# ATtiny416 device description
Architecture: AVR8X; Family: AVR TINY
Registers are 8-bit, read-write, reset 0x0 unless marked. A register's access mark holds for its fields unless they carry their own. Offsets are from the block's base; [hi:lo] are bit positions.

## CPU
Instances: CPU 0x0030
0x04 CCP — Configuration Change Protection
  [7:0] CCP — CCP signature
    157=SPM (SPM Instruction Protection); 216=IOREG (IO Register Protection)
0x0D SPL reset not defined — Stack Pointer Low
0x0E SPH reset not defined — Stack Pointer High
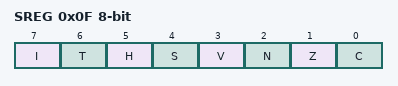
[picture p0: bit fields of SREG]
0x0F SREG — Status Register
  [7] I — Global Interrupt Enable Flag
  [6] T — Transfer Bit
  [5] H — Half Carry Flag
  [4] S — N Exclusive Or V Flag
  [3] V — Two's Complement Overflow Flag
  [2] N — Negative Flag
  [1] Z — Zero Flag
  [0] C — Carry Flag

## CPUINT — Interrupt Controller
Instances: CPUINT 0x0110
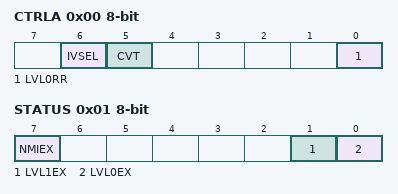
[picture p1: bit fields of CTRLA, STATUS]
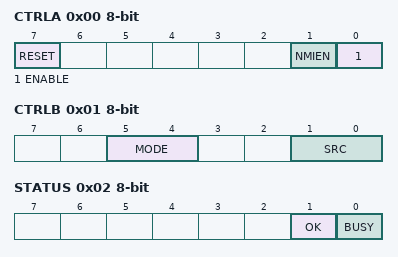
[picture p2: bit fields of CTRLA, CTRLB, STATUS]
0x00 CTRLA — Control A
  [6] IVSEL — Interrupt Vector Select
  [5] CVT — Compact Vector Table
  [0] LVL0RR — Round-robin Scheduling Enable
0x01 STATUS
  [7] NMIEX ro — Non-maskable Interrupt Executing
  [1] LVL1EX ro — Level 1 Interrupt Executing
  [0] LVL0EX ro — Level 0 Interrupt Executing
0x02 LVL0PRI — Interrupt Level 0 Priority
  [7:0] LVL0PRI — Interrupt Level Priority
0x03 LVL1VEC — Interrupt Level 1 Priority Vector
  [7:0] LVL1VEC — Interrupt Vector with High Priority

## CRCSCAN
Instances: CRCSCAN 0x0120
0x00 CTRLA — Control A
  [7] RESET — Reset CRC scan
  [1] NMIEN — Enable NMI Trigger
  [0] ENABLE — Enable CRC scan
0x01 CTRLB — Control B
  [5:4] MODE — CRC Flash Access Mode
    0=PRIORITY (Priority to flash); 2=BACKGROUND (Lowest priority to flash); 3=CONTINUOUS (Continuous checks in background)
  [1:0] SRC — CRC Source
    0=FLASH (CRC on entire flash); 1=APPLICATION (CRC on boot and appl section of flash); 2=BOOT (CRC on boot section of flash)
0x02 STATUS ro
  [1] OK — CRC Ok
  [0] BUSY — CRC Busy

## DAC — Digital to Analog Converter
Instances: DAC0 0x0680
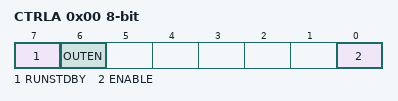
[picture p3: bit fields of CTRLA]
0x00 CTRLA — Control Register A
  [7] RUNSTDBY — Run in Standby Mode
  [6] OUTEN — Output Buffer Enable
  [0] ENABLE — DAC Enable
0x01 DATA reset not defined

## FUSE — Fuses
Instances: FUSE 0x1280
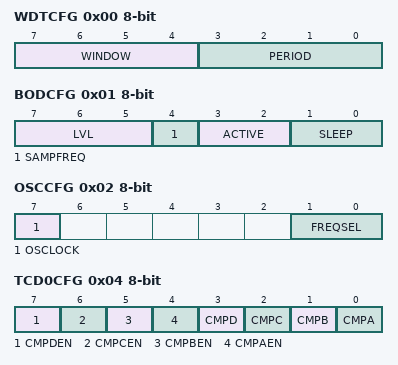
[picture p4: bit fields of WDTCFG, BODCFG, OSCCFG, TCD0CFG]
0x00 WDTCFG — Watchdog Configuration
  [7:4] WINDOW — Watchdog Window Timeout Period
    0=OFF (Window mode off); 1=8CLK (8 cycles (8ms)); 2=16CLK (16 cycles (16ms)); 3=32CLK (32 cycles (32ms)); 4=64CLK (64 cycles (64ms)); 5=128CLK (128 cycles (0.128s)); 6=256CLK (256 cycles (0.256s)); 7=512CLK (512 cycles (0.512s)); 8=1KCLK (1K cycles (1.0s)); 9=2KCLK (2K cycles (2.0s)); 10=4KCLK (4K cycles (4.1s)); 11=8KCLK (8K cycles (8.2s))
  [3:0] PERIOD — Watchdog Timeout Period
    0=OFF (Watch-Dog timer Off); 1=8CLK (8 cycles (8ms)); 2=16CLK (16 cycles (16ms)); 3=32CLK (32 cycles (32ms)); 4=64CLK (64 cycles (64ms)); 5=128CLK (128 cycles (0.128s)); 6=256CLK (256 cycles (0.256s)); 7=512CLK (512 cycles (0.512s)); 8=1KCLK (1K cycles (1.0s)); 9=2KCLK (2K cycles (2.0s)); 10=4KCLK (4K cycles (4.1s)); 11=8KCLK (8K cycles (8.2s))
0x01 BODCFG — BOD Configuration
  [7:5] LVL — BOD Level
    0=BODLEVEL0 (1.8 V); 1=BODLEVEL1 (2.1 V); 2=BODLEVEL2 (2.6 V); 3=BODLEVEL3 (2.9 V); 4=BODLEVEL4 (3.3 V); 5=BODLEVEL5 (3.7 V); 6=BODLEVEL6 (4.0 V); 7=BODLEVEL7 (4.2 V)
  [4] SAMPFREQ — BOD Sample Frequency
    0=1kHz sampling frequency; 1=125Hz sampling frequency
  [3:2] ACTIVE — BOD Operation in Active Mode
    0=DIS (Disabled); 1=ENABLED; 2=SAMPLED; 3=ENWAKE (Enabled with wake-up halted until BOD is ready)
  [1:0] SLEEP — BOD Operation in Sleep Mode
    0=DIS (Disabled); 1=ENABLED; 2=SAMPLED
0x02 OSCCFG — Oscillator Configuration
  [7] OSCLOCK — Oscillator Lock
  [1:0] FREQSEL — Frequency Select
    1=16MHZ; 2=20MHZ
0x04 TCD0CFG — TCD0 Configuration
  [7] CMPDEN — Compare D Output Enable
  [6] CMPCEN — Compare C Output Enable
  [5] CMPBEN — Compare B Output Enable
  [4] CMPAEN — Compare A Output Enable
  [3] CMPD — Compare D Default Output Value
  [2] CMPC — Compare C Default Output Value
  [1] CMPB — Compare B Default Output Value
  [0] CMPA — Compare A Default Output Value
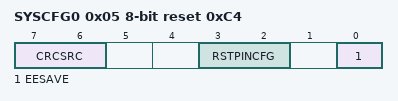
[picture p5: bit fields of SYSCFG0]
0x05 SYSCFG0 reset 0xC4 — System Configuration 0
  [7:6] CRCSRC — CRC Source
    0=FLASH (The CRC is performed on the entire Flash (boot, application code and application data section).); 1=BOOT (The CRC is performed on the boot section of Flash); 2=BOOTAPP (The CRC is performed on the boot and application code section of Flash); 3=NOCRC (Disable CRC.)
  [3:2] RSTPINCFG — Reset Pin Configuration
    0=GPIO (GPIO mode); 1=UPDI (UPDI mode); 2=RST (Reset mode)
  [0] EESAVE — EEPROM Save
0x06 SYSCFG1 — System Configuration 1
  [2:0] SUT — Startup Time
    0=0MS; 1=1MS; 2=2MS; 3=4MS; 4=8MS; 5=16MS; 6=32MS; 7=64MS
0x07 APPEND reset not defined — Application Code Section End
0x08 BOOTEND reset not defined — Boot Section End
